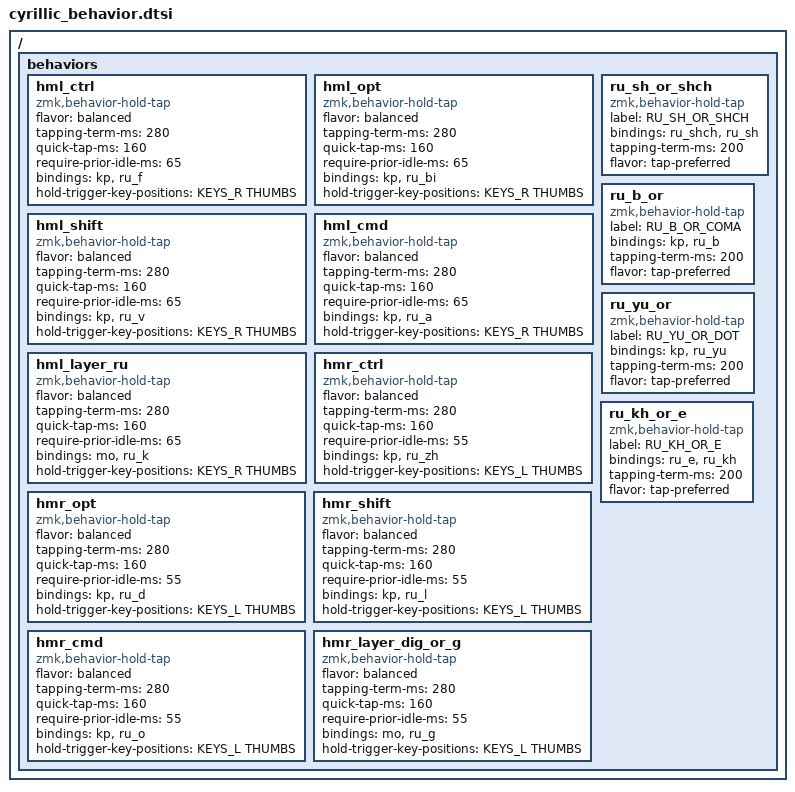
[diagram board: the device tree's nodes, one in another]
 / {
     behaviors {

         // Left-hand HRM
         hml_ctrl: hml_ctrl {
             compatible = "zmk,behavior-hold-tap";
             #binding-cells = <2>;
             flavor = "balanced";
             tapping-term-ms = <280>;
             quick-tap-ms = <160>;
             require-prior-idle-ms = <65>;
             bindings = <&kp>, <&ru_f>;
             hold-trigger-key-positions = <KEYS_R THUMBS>;
         };

          // Left-hand HRM
          hml_opt: hml_opt {
              compatible = "zmk,behavior-hold-tap";
              #binding-cells = <2>;
              flavor = "balanced";
              tapping-term-ms = <280>;
              quick-tap-ms = <160>;
              require-prior-idle-ms = <65>;
              bindings = <&kp>, <&ru_bi>;
              hold-trigger-key-positions = <KEYS_R THUMBS>;
          };

           // Left-hand HRM
           hml_shift: hml_shift {
               compatible = "zmk,behavior-hold-tap";
               #binding-cells = <2>;
               flavor = "balanced";
               tapping-term-ms = <280>;
               quick-tap-ms = <160>;
               require-prior-idle-ms = <65>;
               bindings = <&kp>, <&ru_v>;
               hold-trigger-key-positions = <KEYS_R THUMBS>;
           };

          // Left-hand HRM
          hml_cmd: hml_cmd {
              compatible = "zmk,behavior-hold-tap";
              #binding-cells = <2>;
              flavor = "balanced";
              tapping-term-ms = <280>;
              quick-tap-ms = <160>;
              require-prior-idle-ms = <65>;
              bindings = <&kp>, <&ru_a>;
              hold-trigger-key-positions = <KEYS_R THUMBS>;
          };

            // Left-hand HRM
            hml_layer_ru: hml_layer_ru {
                compatible = "zmk,behavior-hold-tap";
                #binding-cells = <2>;
                flavor = "balanced";
                tapping-term-ms = <280>;
                quick-tap-ms = <160>;
                require-prior-idle-ms = <65>;
                bindings = <&mo>, <&ru_k>;
                hold-trigger-key-positions = <KEYS_R THUMBS>;
            };

         // Right-hand HRM
         hmr_ctrl: hmr_ctrl {
             compatible = "zmk,behavior-hold-tap";
             #binding-cells = <2>;
             flavor = "balanced";
             tapping-term-ms = <280>;
             quick-tap-ms = <160>;
             require-prior-idle-ms = <55>;
             bindings = <&kp>, <&ru_zh>;
             hold-trigger-key-positions = <KEYS_L THUMBS>;
         };

          // Right-hand HRM
          hmr_opt: hmr_opt {
              compatible = "zmk,behavior-hold-tap";
              #binding-cells = <2>;
              flavor = "balanced";
              tapping-term-ms = <280>;
              quick-tap-ms = <160>;
              require-prior-idle-ms = <55>;
              bindings = <&kp>, <&ru_d>;
              hold-trigger-key-positions = <KEYS_L THUMBS>;
          };

           // Right-hand HRM
           hmr_shift: hmr_shift {
               compatible = "zmk,behavior-hold-tap";
               #binding-cells = <2>;
               flavor = "balanced";
               tapping-term-ms = <280>;
               quick-tap-ms = <160>;
               require-prior-idle-ms = <55>;
               bindings = <&kp>, <&ru_l>;
               hold-trigger-key-positions = <KEYS_L THUMBS>;
           };

            // Right-hand HRM
            hmr_cmd: hmr_cmd {
                compatible = "zmk,behavior-hold-tap";
                #binding-cells = <2>;
                flavor = "balanced";
                tapping-term-ms = <280>;
                quick-tap-ms = <160>;
                require-prior-idle-ms = <55>;
                bindings = <&kp>, <&ru_o>;
                hold-trigger-key-positions = <KEYS_L THUMBS>;
            };

            // Right-hand HRM
            hmr_layer_dig_or_g: hmr_layer_dig_or_g {
                compatible = "zmk,behavior-hold-tap";
                #binding-cells = <2>;
                flavor = "balanced";
                tapping-term-ms = <280>;
                quick-tap-ms = <160>;
                require-prior-idle-ms = <55>;
                bindings = <&mo>, <&ru_g>;
                hold-trigger-key-positions = <KEYS_L THUMBS>;
            };


        ru_sh_or_shch: ru_sh_or_shch {
            compatible = "zmk,behavior-hold-tap";
            label = "RU_SH_OR_SHCH";
            bindings = <&ru_shch>, <&ru_sh>;

            #binding-cells = <2>;
            tapping-term-ms = <200>;
            flavor = "tap-preferred";
        };

        ru_b_or: ru_b_or {
            compatible = "zmk,behavior-hold-tap";
            label = "RU_B_OR_COMA";
            bindings = <&kp>, <&ru_b>;

            #binding-cells = <2>;
            tapping-term-ms = <200>;
            flavor = "tap-preferred";
        };

        ru_yu_or: ru_yu_or {
            compatible = "zmk,behavior-hold-tap";
            label = "RU_YU_OR_DOT";
            bindings = <&kp>, <&ru_yu>;

            #binding-cells = <2>;
            tapping-term-ms = <200>;
            flavor = "tap-preferred";
        };

        ru_kh_or_e: ru_kh_or_e {
            compatible = "zmk,behavior-hold-tap";
            label = "RU_KH_OR_E";
            bindings = <&ru_e>, <&ru_kh>;

            #binding-cells = <2>;
            tapping-term-ms = <200>;
            flavor = "tap-preferred";
        };
     };
 };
